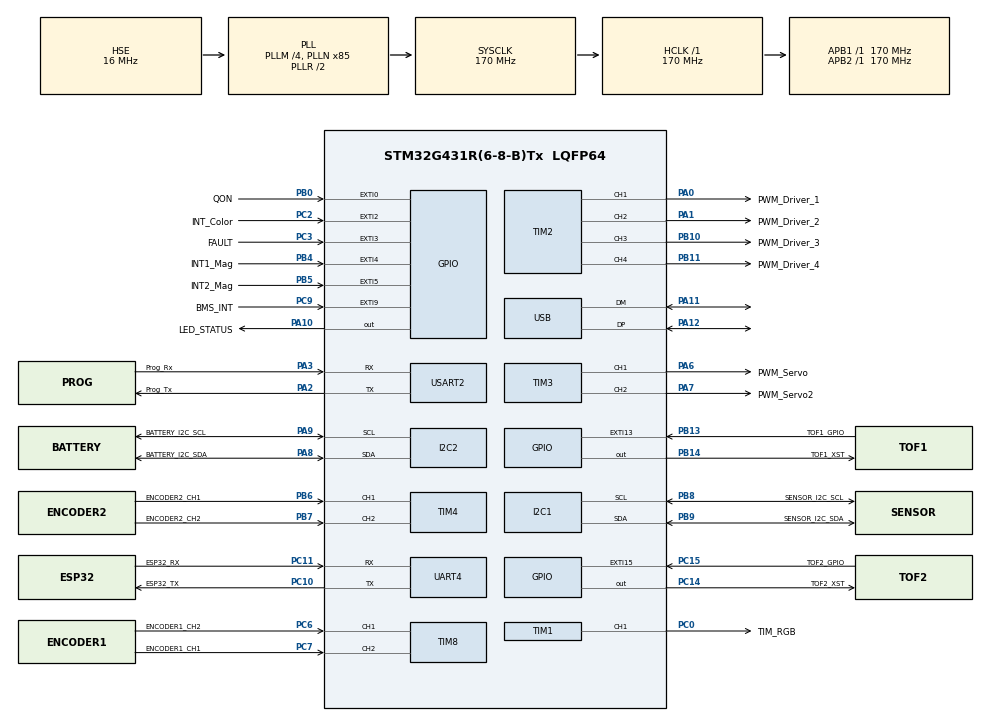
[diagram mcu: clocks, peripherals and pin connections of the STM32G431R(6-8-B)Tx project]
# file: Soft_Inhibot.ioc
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Dma.Request0=TIM1_CH1
Dma.TIM1_CH1.0.Direction=DMA_MEMORY_TO_PERIPH
Dma.TIM1_CH1.0.EventEnable=DISABLE
Dma.TIM1_CH1.0.Instance=DMA1_Channel1
Dma.TIM1_CH1.0.MemDataAlignment=DMA_MDATAALIGN_HALFWORD
Dma.TIM1_CH1.0.MemInc=DMA_MINC_ENABLE
Dma.TIM1_CH1.0.Mode=DMA_NORMAL
Dma.TIM1_CH1.0.PeriphDataAlignment=DMA_PDATAALIGN_HALFWORD
Dma.TIM1_CH1.0.PeriphInc=DMA_PINC_DISABLE
Dma.TIM1_CH1.0.Polarity=HAL_DMAMUX_REQ_GEN_RISING
Dma.TIM1_CH1.0.Priority=DMA_PRIORITY_LOW
Dma.TIM1_CH1.0.RequestNumber=1
Dma.TIM1_CH1.0.SignalID=NONE
Dma.TIM1_CH1.0.SyncEnable=DISABLE
Dma.TIM1_CH1.0.SyncPolarity=HAL_DMAMUX_SYNC_NO_EVENT
Dma.TIM1_CH1.0.SyncRequestNumber=1
Dma.TIM1_CH1.0.SyncSignalID=NONE
I2C1.Timing=0x40B285C2
I2C2.Timing=0x40B285C2
Mcu.Family=STM32G4
Mcu.Name=STM32G431R(6-8-B)Tx
Mcu.Package=LQFP64
NVIC.DMA1_Channel1_IRQn=true\:0\:0\:false\:false\:true\:false\:true\:true
NVIC.PriorityGroup=NVIC_PRIORITYGROUP_4
PA0.GPIO_Label=PWM_Driver_1
PA0.Signal=S_TIM2_CH1
PA1.GPIO_Label=PWM_Driver_2
PA1.Signal=S_TIM2_CH2
PA10.GPIO_Label=LED_STATUS
PA10.Signal=GPIO_Output
PA11.Mode=Device
PA11.Signal=USB_DM
PA12.Mode=Device
PA12.Signal=USB_DP
PA13.Mode=Serial_Wire
PA13.Signal=SYS_JTMS-SWDIO
PA14.Mode=Serial_Wire
PA14.Signal=SYS_JTCK-SWCLK
PA2.GPIO_Label=Prog_Tx
PA2.Mode=Asynchronous
PA2.Signal=USART2_TX
PA3.GPIO_Label=Prog_Rx
PA3.Mode=Asynchronous
PA3.Signal=USART2_RX
PA6.GPIO_Label=PWM_Servo
PA6.Signal=S_TIM3_CH1
PA7.GPIO_Label=PWM_Servo2
PA7.Signal=S_TIM3_CH2
PA8.GPIO_Label=BATTERY_I2C_SDA
PA8.Mode=I2C
PA8.Signal=I2C2_SDA
PA9.GPIO_Label=BATTERY_I2C_SCL
PA9.Mode=I2C
PA9.Signal=I2C2_SCL
PB0.GPIO_Label=QON
PB0.Signal=GPXTI0
PB10.GPIO_Label=PWM_Driver_3
PB10.Signal=S_TIM2_CH3
PB11.GPIO_Label=PWM_Driver_4
PB11.Signal=S_TIM2_CH4
PB13.GPIO_Label=TOF1_GPIO
PB13.Signal=GPXTI13
PB14.GPIO_Label=TOF1_XST
PB14.Signal=GPIO_Output
PB3.Signal=SYS_JTDO-SWO
PB4.GPIO_Label=INT1_Mag
PB4.Signal=GPXTI4
PB5.GPIO_Label=INT2_Mag
PB5.Signal=GPXTI5
PB6.GPIO_Label=ENCODER2_CH1
PB6.Signal=S_TIM4_CH1
PB7.GPIO_Label=ENCODER2_CH2
PB7.Signal=S_TIM4_CH2
PB8-BOOT0.GPIO_Label=SENSOR_I2C_SCL
PB8-BOOT0.Mode=I2C
PB8-BOOT0.Signal=I2C1_SCL
PB9.GPIO_Label=SENSOR_I2C_SDA
PB9.Mode=I2C
PB9.Signal=I2C1_SDA
PC0.GPIO_Label=TIM_RGB
PC0.Signal=S_TIM1_CH1
PC10.GPIO_Label=ESP32_TX
PC10.Mode=Asynchronous
PC10.Signal=UART4_TX
PC11.GPIO_Label=ESP32_RX
PC11.Mode=Asynchronous
PC11.Signal=UART4_RX
PC14-OSC32_IN.GPIO_Label=TOF2_XST
PC14-OSC32_IN.Signal=GPIO_Output
PC15-OSC32_OUT.GPIO_Label=TOF2_GPIO
PC15-OSC32_OUT.Signal=GPXTI15
PC2.GPIO_Label=INT_Color
PC2.Signal=GPXTI2
PC3.GPIO_Label=FAULT
PC3.Signal=GPXTI3
PC6.GPIO_Label=ENCODER1_CH2
PC6.Signal=S_TIM8_CH1
PC7.GPIO_Label=ENCODER1_CH1
PC7.Signal=S_TIM8_CH2
PC9.GPIO_Label=BMS_INT
PC9.Signal=GPXTI9
PF0-OSC_IN.Mode=HSE-External-Oscillator
PF0-OSC_IN.Signal=RCC_OSC_IN
PF1-OSC_OUT.Mode=HSE-External-Oscillator
PF1-OSC_OUT.Signal=RCC_OSC_OUT
ProjectManager.HeapSize=0x200
ProjectManager.StackSize=0x400
ProjectManager.TargetToolchain=CMake
RCC.ADC12Freq_Value=170000000
RCC.AHBFreq_Value=170000000
RCC.APB1Freq_Value=170000000
RCC.APB1TimFreq_Value=170000000
RCC.APB2Freq_Value=170000000
RCC.APB2TimFreq_Value=170000000
RCC.CK48CLockSelection=RCC_USBCLKSOURCE_HSI48
RCC.CortexFreq_Value=170000000
RCC.EXTERNAL_CLOCK_VALUE=12288000
RCC.HCLKFreq_Value=170000000
RCC.HSE_VALUE=16000000
RCC.HSI48_VALUE=48000000
RCC.HSI_VALUE=16000000
RCC.LSE_VALUE=32768
RCC.PLLM=RCC_PLLM_DIV4
RCC.PLLN=85
RCC.PLLSourceVirtual=RCC_PLLSOURCE_HSE
RCC.SYSCLKFreq_VALUE=170000000
RCC.SYSCLKSource=RCC_SYSCLKSOURCE_PLLCLK
RCC.USBFreq_Value=48000000
RCC.VCOOutputFreq_Value=340000000
SH.S_TIM1_CH1.0=TIM1_CH1,PWM Generation1 CH1
SH.S_TIM2_CH1.0=TIM2_CH1,PWM Generation1 CH1
SH.S_TIM2_CH2.0=TIM2_CH2,PWM Generation2 CH2
SH.S_TIM2_CH3.0=TIM2_CH3,PWM Generation3 CH3
SH.S_TIM2_CH4.0=TIM2_CH4,PWM Generation4 CH4
SH.S_TIM3_CH1.0=TIM3_CH1,PWM Generation1 CH1
SH.S_TIM3_CH2.0=TIM3_CH2,PWM Generation2 CH2
SH.S_TIM4_CH1.0=TIM4_CH1,Encoder_Interface
SH.S_TIM4_CH2.0=TIM4_CH2,Encoder_Interface
SH.S_TIM8_CH1.0=TIM8_CH1,Encoder_Interface
SH.S_TIM8_CH2.0=TIM8_CH2,Encoder_Interface
TIM1.Channel-PWM\ Generation1\ CH1=TIM_CHANNEL_1
TIM2.Channel-PWM\ Generation1\ CH1=TIM_CHANNEL_1
TIM2.Channel-PWM\ Generation2\ CH2=TIM_CHANNEL_2
TIM2.Channel-PWM\ Generation3\ CH3=TIM_CHANNEL_3
TIM2.Channel-PWM\ Generation4\ CH4=TIM_CHANNEL_4
TIM3.Channel-PWM\ Generation1\ CH1=TIM_CHANNEL_1
TIM3.Channel-PWM\ Generation2\ CH2=TIM_CHANNEL_2
USART2.VirtualMode-Asynchronous=VM_ASYNC
VP_SYS_VS_DBSignals.Mode=DisableDeadBatterySignals
VP_TIM6_VS_ClockSourceINT.Mode=Enable_Timer
board=custom

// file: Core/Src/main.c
/* USER CODE BEGIN Header */
/**
  ******************************************************************************
  * @file           : main.c
  * @brief          : Main program body
  ******************************************************************************
  * @attention
  *
  * Copyright (c) 2026 STMicroelectronics.
  * All rights reserved.
  *
  * This software is licensed under terms that can be found in the LICENSE file
  * in the root directory of this software component.
  * If no LICENSE file comes with this software, it is provided AS-IS.
  *
  ******************************************************************************
  */
/* USER CODE END Header */
#include "main.h"
#include "dma.h"
#include "i2c.h"
#include "tim.h"
#include "usart.h"
#include "usb.h"
#include "gpio.h"
#include "test.h"

/* USER CODE BEGIN Includes */
#include <stdio.h>
/* USER CODE END Includes */

void SystemClock_Config(void);

/* USER CODE BEGIN 0 */
int __io_putchar(int ch) {
	HAL_UART_Transmit(&huart2, (uint8_t*) &ch, 1, HAL_MAX_DELAY);
	return ch;
}

/* USER CODE END 0 */

int main(void)
{

  /* MCU Configuration--------------------------------------------------------*/

  /* Reset of all peripherals, Initializes the Flash interface and the Systick. */
  HAL_Init();

  /* Configure the system clock */
  SystemClock_Config();

  /* Initialize all configured peripherals */
  MX_GPIO_Init();
  MX_DMA_Init();
  MX_I2C1_Init();
  MX_UART4_Init();
  MX_TIM2_Init();
  MX_TIM3_Init();
  MX_TIM1_Init();
  MX_TIM4_Init();
  MX_TIM8_Init();
  MX_USART2_UART_Init();
  MX_USB_PCD_Init();
  MX_I2C2_Init();
  MX_TIM6_Init();
  /* USER CODE BEGIN 2 */
  printf("Hello World! \r\n");
  setup_rgb();
  const uint8_t rgb_hues[] = {0U, 85U, 170U};
  uint8_t rgb_color_index = 0U;
  set_led_hsv(0U, rgb_hues[rgb_color_index], 255U, 30U);
  uint32_t last_rgb_change = HAL_GetTick();
  uint32_t last_status_toggle = HAL_GetTick();
  /* USER CODE END 2 */

  /* Infinite loop */
  while (1)
  {
    if ((HAL_GetTick() - last_rgb_change) >= 500U)
    {
      rgb_color_index = (uint8_t)((rgb_color_index + 1U) % 3U);
      set_led_hsv(0U, rgb_hues[rgb_color_index], 255U, 30U);
      last_rgb_change = HAL_GetTick();
    }
    if ((HAL_GetTick() - last_status_toggle) >= 500U)
    {
      HAL_GPIO_TogglePin(LED_STATUS_GPIO_Port, LED_STATUS_Pin);
      last_status_toggle = HAL_GetTick();
    }
    HAL_Delay(20U);
  }
}

void SystemClock_Config(void)
{
  RCC_OscInitTypeDef RCC_OscInitStruct = {0};
  RCC_ClkInitTypeDef RCC_ClkInitStruct = {0};

  /** Configure the main internal regulator output voltage
  */
  HAL_PWREx_ControlVoltageScaling(PWR_REGULATOR_VOLTAGE_SCALE1_BOOST);

  /** Initializes the RCC Oscillators according to the specified parameters
  * in the RCC_OscInitTypeDef structure.
  */
  RCC_OscInitStruct.OscillatorType = RCC_OSCILLATORTYPE_HSI48|RCC_OSCILLATORTYPE_HSE;
  RCC_OscInitStruct.HSEState = RCC_HSE_ON;
  RCC_OscInitStruct.HSI48State = RCC_HSI48_ON;
  RCC_OscInitStruct.PLL.PLLState = RCC_PLL_ON;
  RCC_OscInitStruct.PLL.PLLSource = RCC_PLLSOURCE_HSE;
  RCC_OscInitStruct.PLL.PLLM = RCC_PLLM_DIV4;
  RCC_OscInitStruct.PLL.PLLN = 85;
  RCC_OscInitStruct.PLL.PLLP = RCC_PLLP_DIV2;
  RCC_OscInitStruct.PLL.PLLQ = RCC_PLLQ_DIV2;
  RCC_OscInitStruct.PLL.PLLR = RCC_PLLR_DIV2;
  if (HAL_RCC_OscConfig(&RCC_OscInitStruct) != HAL_OK)
  {
    Error_Handler();
  }

  /** Initializes the CPU, AHB and APB buses clocks
  */
  RCC_ClkInitStruct.ClockType = RCC_CLOCKTYPE_HCLK|RCC_CLOCKTYPE_SYSCLK
                              |RCC_CLOCKTYPE_PCLK1|RCC_CLOCKTYPE_PCLK2;
  RCC_ClkInitStruct.SYSCLKSource = RCC_SYSCLKSOURCE_PLLCLK;
  RCC_ClkInitStruct.AHBCLKDivider = RCC_SYSCLK_DIV1;
  RCC_ClkInitStruct.APB1CLKDivider = RCC_HCLK_DIV1;
  RCC_ClkInitStruct.APB2CLKDivider = RCC_HCLK_DIV1;

  if (HAL_RCC_ClockConfig(&RCC_ClkInitStruct, FLASH_LATENCY_4) != HAL_OK)
  {
    Error_Handler();
  }
}

void Error_Handler(void)
{
  __disable_irq();
  while (1)
  {
  }
}
